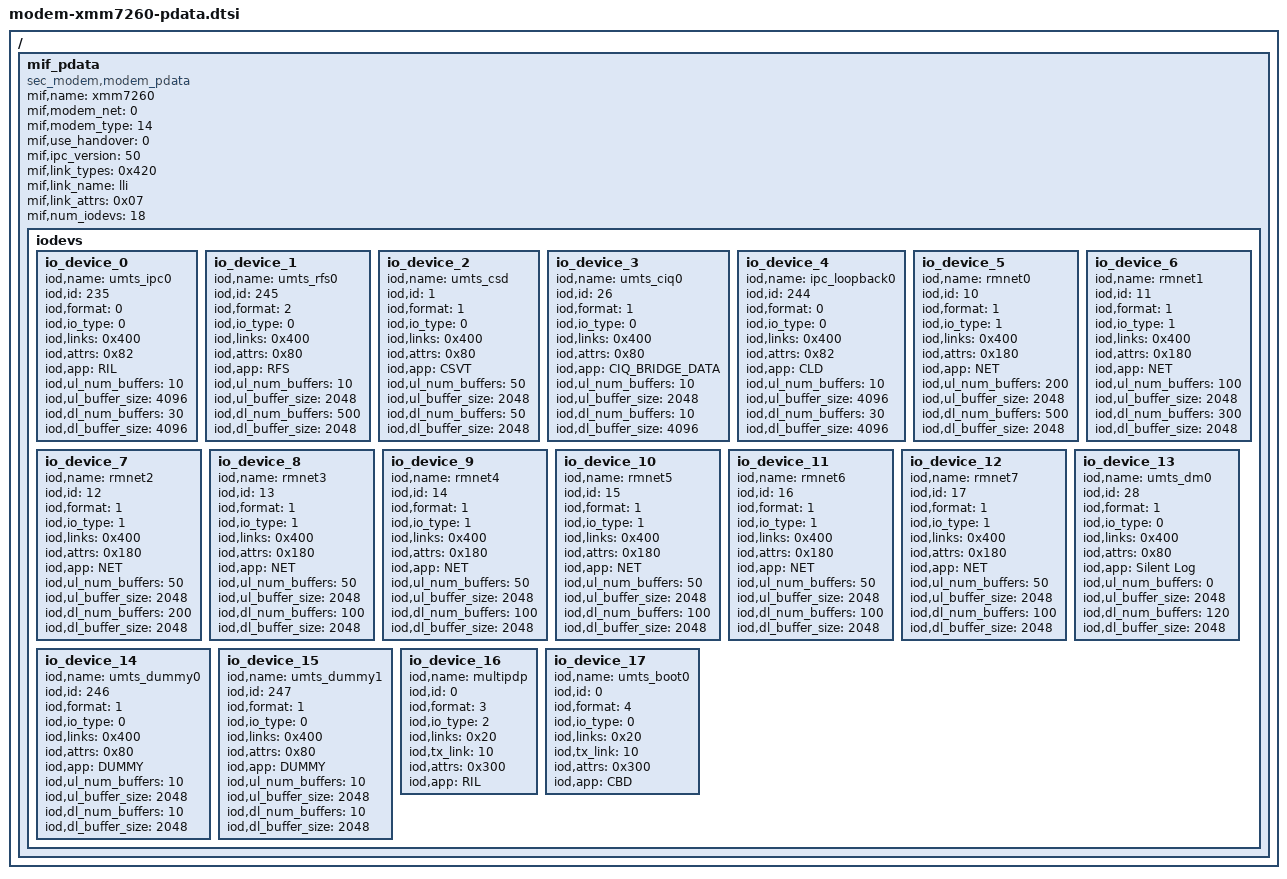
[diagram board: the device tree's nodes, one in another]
/*
 * SAMSUNG UNIVERSAL5430 board device tree source
 *
 * Copyright (c) 2013 Samsung Electronics Co., Ltd.
 *		http://www.samsung.com
 *
 * This program is free software; you can redistribute it and/or modify
 * it under the terms of the GNU General Public License version 2 as
 * published by the Free Software Foundation.
*/

/ {
	/* modem_interface_driver: Intel XMM7260 LTE Modem */
	mif_pdata {
		compatible = "sec_modem,modem_pdata";

		mif,name = "xmm7260";	/* xmm7260 */
		mif,modem_net = <0>;
		mif,modem_type = <14>;
		mif,use_handover = <0>;
		mif,ipc_version = <50>;
		mif,link_types = <0x420>;	/* LINKDEV_LLI | LINKDEV_HSIC */
		mif,link_name = "lli";
		mif,link_attrs = <0x07>;	/* IOSM_MESSAGE (0x04) | IPC_ALIGNED (0x02) | SBD_IPC (0x01) */

		mif,num_iodevs = <18>;
		iodevs {
			io_device_0 {
				iod,name = "umts_ipc0";
				iod,id = <235>;
				iod,format = <0>;
				iod,io_type = <0>;
				iod,links = <0x400>;
				iod,attrs = <0x82>;	/* ATTR_SBD_IPC | ATTR_SIPC5 */
				iod,app = "RIL";
				iod,ul_num_buffers = <10>;
				iod,ul_buffer_size = <4096>;
				iod,dl_num_buffers = <30>;
				iod,dl_buffer_size = <4096>;
			};
			io_device_1 {
				iod,name = "umts_rfs0";
				iod,id = <245>;
				iod,format = <2>;
				iod,io_type = <0>;
				iod,links = <0x400>;
				iod,attrs = <0x80>;
				iod,app = "RFS";
				iod,ul_num_buffers = <10>;
				iod,ul_buffer_size = <2048>;
				iod,dl_num_buffers = <500>;
				iod,dl_buffer_size = <2048>;
			};
			io_device_2 {
				iod,name = "umts_csd";
				iod,id = <1>;
				iod,format = <1>;
				iod,io_type = <0>;
				iod,links = <0x400>;	/* LINKDEV_LLI */
				iod,attrs = <0x80>;
				iod,app = "CSVT";
				iod,ul_num_buffers = <50>;
				iod,ul_buffer_size = <2048>;
				iod,dl_num_buffers = <50>;
				iod,dl_buffer_size = <2048>;
			};
			io_device_3 {
				iod,name = "umts_ciq0";
				iod,id = <26>;
				iod,format = <1>;
				iod,io_type = <0>;
				iod,links = <0x400>;
				iod,attrs = <0x80>;
				iod,app = "CIQ_BRIDGE_DATA";
				iod,ul_num_buffers = <10>;
				iod,ul_buffer_size = <2048>;
				iod,dl_num_buffers = <10>;
				iod,dl_buffer_size = <4096>;
			};
			io_device_4 {
				iod,name = "ipc_loopback0";
				iod,id = <244>;
				iod,format = <0>;
				iod,io_type = <0>;
				iod,links = <0x400>;
				iod,attrs = <0x82>;	/* ATTR_SBD_IPC | ATTR_SIPC5 */
				iod,app = "CLD";
				iod,ul_num_buffers = <10>;
				iod,ul_buffer_size = <4096>;
				iod,dl_num_buffers = <30>;
				iod,dl_buffer_size = <4096>;
			};
			io_device_5 {
				iod,name = "rmnet0";
				iod,id = <10>;
				iod,format = <1>;
				iod,io_type = <1>;
				iod,links = <0x400>;
				iod,attrs = <0x180>;
				iod,app = "NET";
				iod,ul_num_buffers = <200>;
				iod,ul_buffer_size = <2048>;
				iod,dl_num_buffers = <500>;
				iod,dl_buffer_size = <2048>;
			};
			io_device_6 {
				iod,name = "rmnet1";
				iod,id = <11>;
				iod,format = <1>;
				iod,io_type = <1>;
				iod,links = <0x400>;
				iod,attrs = <0x180>;
				iod,app = "NET";
				iod,ul_num_buffers = <100>;
				iod,ul_buffer_size = <2048>;
				iod,dl_num_buffers = <300>;
				iod,dl_buffer_size = <2048>;
			};
			io_device_7 {
				iod,name = "rmnet2";
				iod,id = <12>;
				iod,format = <1>;
				iod,io_type = <1>;
				iod,links = <0x400>;
				iod,attrs = <0x180>;
				iod,app = "NET";
				iod,ul_num_buffers = <50>;
				iod,ul_buffer_size = <2048>;
				iod,dl_num_buffers = <200>;
				iod,dl_buffer_size = <2048>;
			};
			io_device_8 {
				iod,name = "rmnet3";
				iod,id = <13>;
				iod,format = <1>;
				iod,io_type = <1>;
				iod,links = <0x400>;
				iod,attrs = <0x180>;
				iod,app = "NET";
				iod,ul_num_buffers = <50>;
				iod,ul_buffer_size = <2048>;
				iod,dl_num_buffers = <100>;
				iod,dl_buffer_size = <2048>;
			};
			io_device_9 {
				iod,name = "rmnet4";
				iod,id = <14>;
				iod,format = <1>;
				iod,io_type = <1>;
				iod,links = <0x400>;
				iod,attrs = <0x180>;
				iod,app = "NET";
				iod,ul_num_buffers = <50>;
				iod,ul_buffer_size = <2048>;
				iod,dl_num_buffers = <100>;
				iod,dl_buffer_size = <2048>;
			};
			io_device_10 {
				iod,name = "rmnet5";
				iod,id = <15>;
				iod,format = <1>;
				iod,io_type = <1>;
				iod,links = <0x400>;
				iod,attrs = <0x180>;
				iod,app = "NET";
				iod,ul_num_buffers = <50>;
				iod,ul_buffer_size = <2048>;
				iod,dl_num_buffers = <100>;
				iod,dl_buffer_size = <2048>;
			};
			io_device_11 {
				iod,name = "rmnet6";
				iod,id = <16>;
				iod,format = <1>;
				iod,io_type = <1>;
				iod,links = <0x400>;
				iod,attrs = <0x180>;
				iod,app = "NET";
				iod,ul_num_buffers = <50>;
				iod,ul_buffer_size = <2048>;
				iod,dl_num_buffers = <100>;
				iod,dl_buffer_size = <2048>;
			};
			io_device_12 {
				iod,name = "rmnet7";
				iod,id = <17>;
				iod,format = <1>;
				iod,io_type = <1>;
				iod,links = <0x400>;
				iod,attrs = <0x180>;
				iod,app = "NET";
				iod,ul_num_buffers = <50>;
				iod,ul_buffer_size = <2048>;
				iod,dl_num_buffers = <100>;
				iod,dl_buffer_size = <2048>;
			};
			io_device_13 {
				iod,name = "umts_dm0";
				iod,id = <28>;
				iod,format = <1>;
				iod,io_type = <0>;
				iod,links = <0x400>;
				iod,attrs = <0x80>;
				iod,app = "Silent Log";
				iod,ul_num_buffers = <0>;
				iod,ul_buffer_size = <2048>;
				iod,dl_num_buffers = <120>;
				iod,dl_buffer_size = <2048>;
			};
			io_device_14 {
				iod,name = "umts_dummy0";
				iod,id = <246>;
				iod,format = <1>;
				iod,io_type = <0>;
				iod,links = <0x400>;
				iod,attrs = <0x80>;
				iod,app = "DUMMY";
				iod,ul_num_buffers = <10>;
				iod,ul_buffer_size = <2048>;
				iod,dl_num_buffers = <10>;
				iod,dl_buffer_size = <2048>;
			};
			io_device_15 {
				iod,name = "umts_dummy1";
				iod,id = <247>;
				iod,format = <1>;
				iod,io_type = <0>;
				iod,links = <0x400>;
				iod,attrs = <0x80>;
				iod,app = "DUMMY";
				iod,ul_num_buffers = <10>;
				iod,ul_buffer_size = <2048>;
				iod,dl_num_buffers = <10>;
				iod,dl_buffer_size = <2048>;
			};
			io_device_16 {
				iod,name = "multipdp";
				iod,id = <0>;
				iod,format = <3>;
				iod,io_type = <2>;
				iod,links = <0x20>;	/* LINKDEV_HSIC */
				iod,tx_link = <10>;
				iod,attrs = <0x300>;
				iod,app = "RIL";
			};
			io_device_17 {
				iod,name = "umts_boot0";
				iod,id = <0>;
				iod,format = <4>;
				iod,io_type = <0>;
				iod,links = <0x20>;	/* LINKDEV_HSIC */
				iod,tx_link = <10>;
				iod,attrs = <0x300>;
				iod,app = "CBD";
			};
		}; /* end of iodevs */
	}; /* end of mif_pdata */
};
